# RX64M_ETHERC_Pilot register map
File version: 1.0
RX64M_ETHERC_Pilot peripheral registers generated from iodefine.h (pilot).
Registers are 32-bit, read-write, reset 0x0 unless marked. A register's access mark holds for its fields unless they carry their own. Offsets are from the block's base; lines under a group give offsets from that group; [hi:lo] are bit positions; {n}, {i} and the like mark numbered series; 'fields as' and 'values as' point back to an identical list; <NAME> marks a mode.

## Memory map
0x000C0100 ETHERC0 size 0xFC
0x000C0300 ETHERC1 size 0xFC

## ETHERC0
Base 0x000C0100
Same registers: ETHERC1 0x000C0300
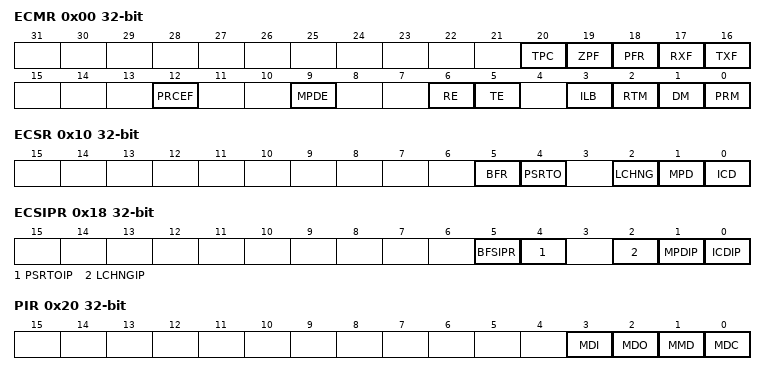
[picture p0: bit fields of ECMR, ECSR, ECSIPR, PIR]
0x00 ECMR
  [20] TPC, [19] ZPF, [18] PFR, [17] RXF, [16] TXF, [12] PRCEF, [9] MPDE, [6] RE, [5] TE, [3] ILB, [2] RTM, [1] DM, [0] PRM
0x08 RFLR
  [11:0] RFL
0x10 ECSR
  [5] BFR, [4] PSRTO, [2] LCHNG, [1] MPD, [0] ICD
0x18 ECSIPR
  [5] BFSIPR, [4] PSRTOIP, [2] LCHNGIP, [1] MPDIP, [0] ICDIP
0x20 PIR (reset mask 0xFFFFFFF7)
  [3] MDI, [2] MDO, [1] MMD, [0] MDC
0x28 PSR ro (reset mask 0xFFFFFFFE)
  [0] LMON
0x40 RDMLR
  [19:0] RMD
0x50 IPGR reset 0x14
  [4:0] IPG
0x54 APR
  [15:0] AP
0x58 MPR (reset mask 0xFFFF0000)
  [15:0] MP
0x60 RFCF ro
  [7:0] RPAUSE
0x64 TPAUSER
  [15:0] TPAUSE
0x68 TPAUSECR ro
  [7:0] TXP
0x6C BCFRR
  [15:0] BCF
0xC0 MAHR
0xC8 MALR
  [15:0] MA
0xD0 TROCR
0xD4 CDCR
0xD8 LCCR
0xDC CNDCR
0xE4 CEFCR
0xE8 FRECR
0xEC TSFRCR
0xF0 TLFRCR
0xF4 RFCR
0xF8 MAFCR
